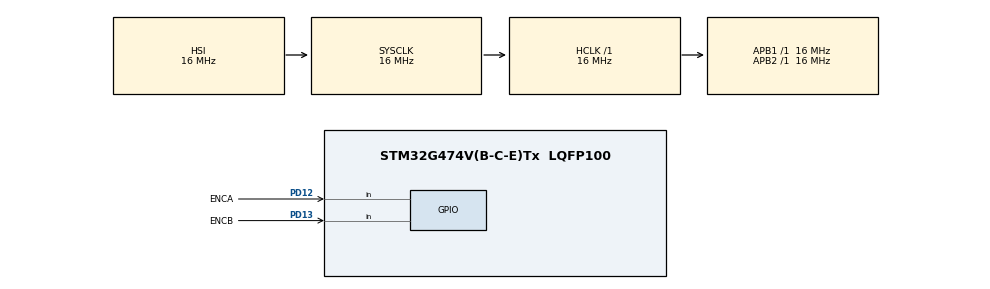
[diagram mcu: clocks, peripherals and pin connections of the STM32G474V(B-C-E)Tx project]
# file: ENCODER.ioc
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Mcu.Family=STM32G4
Mcu.Name=STM32G474V(B-C-E)Tx
Mcu.Package=LQFP100
NVIC.PriorityGroup=NVIC_PRIORITYGROUP_4
PD12.GPIO_Label=ENCA
PD12.GPIO_PuPd=GPIO_PULLUP
PD12.Signal=GPIO_Input
PD13.GPIO_Label=ENCB
PD13.GPIO_PuPd=GPIO_PULLUP
PD13.Signal=GPIO_Input
ProjectManager.HeapSize=0x200
ProjectManager.StackSize=0x400
ProjectManager.TargetToolchain=STM32CubeIDE
RCC.AHBFreq_Value=16000000
RCC.APB1Freq_Value=16000000
RCC.APB1TimFreq_Value=16000000
RCC.APB2Freq_Value=16000000
RCC.APB2TimFreq_Value=16000000
RCC.CortexFreq_Value=16000000
RCC.EXTERNAL_CLOCK_VALUE=12288000
RCC.HCLKFreq_Value=16000000
RCC.HSE_VALUE=8000000
RCC.HSI48_VALUE=48000000
RCC.HSI_VALUE=16000000
RCC.LSE_VALUE=32768
RCC.SYSCLKFreq_VALUE=16000000
RCC.USBFreq_Value=64000000
RCC.VCOOutputFreq_Value=128000000
board=custom

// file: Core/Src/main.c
/* USER CODE BEGIN Header */
/**
  ******************************************************************************
  * @file           : main.c
  * @brief          : Main program body
  ******************************************************************************
  * @attention
  *
  * Copyright (c) 2025 STMicroelectronics.
  * All rights reserved.
  *
  * This software is licensed under terms that can be found in the LICENSE file
  * in the root directory of this software component.
  * If no LICENSE file comes with this software, it is provided AS-IS.
  *
  ******************************************************************************
  */
/* USER CODE END Header */
#include "main.h"

void SystemClock_Config(void);
static void MX_GPIO_Init(void);

/* USER CODE BEGIN 0 */
int encoder = 0;
/* USER CODE END 0 */

int main(void)
{

  /* MCU Configuration--------------------------------------------------------*/

  /* Reset of all peripherals, Initializes the Flash interface and the Systick. */
  HAL_Init();

  /* Configure the system clock */
  SystemClock_Config();

  /* Initialize all configured peripherals */
  MX_GPIO_Init();
  /* USER CODE BEGIN 2 */
int prev = 0b11;
  /* USER CODE END 2 */

  /* Infinite loop */
  while (1)
  {

    /* USER CODE BEGIN 3 */
  	int curr = 0;
  	curr+=HAL_GPIO_ReadPin(ENCA_GPIO_Port, ENCA_Pin) ? 0b01 :0;
  	curr+=HAL_GPIO_ReadPin(ENCB_GPIO_Port, ENCB_Pin) ? 0b10 :0;
  	switch(prev <<2 |curr){
  		case 0b0001:
  		case 0b0111:
  		case 0b1110:
  		case 0b1000:
  			encoder+=1;break; //clockwise
  		case 0b0010:
  		case 0b1011:
  		case 0b1101:
  		case 0b0100:
  			encoder -=1;break;//counterclockwise

  		default: break;

  	}
  	prev = curr;
  	HAL_Delay(0);
  }
  /* USER CODE END 3 */
}

void SystemClock_Config(void)
{
  RCC_OscInitTypeDef RCC_OscInitStruct = {0};
  RCC_ClkInitTypeDef RCC_ClkInitStruct = {0};

  /** Configure the main internal regulator output voltage
  */
  HAL_PWREx_ControlVoltageScaling(PWR_REGULATOR_VOLTAGE_SCALE1);

  /** Initializes the RCC Oscillators according to the specified parameters
  * in the RCC_OscInitTypeDef structure.
  */
  RCC_OscInitStruct.OscillatorType = RCC_OSCILLATORTYPE_HSI;
  RCC_OscInitStruct.HSIState = RCC_HSI_ON;
  RCC_OscInitStruct.HSICalibrationValue = RCC_HSICALIBRATION_DEFAULT;
  RCC_OscInitStruct.PLL.PLLState = RCC_PLL_NONE;
  if (HAL_RCC_OscConfig(&RCC_OscInitStruct) != HAL_OK)
  {
    Error_Handler();
  }

  /** Initializes the CPU, AHB and APB buses clocks
  */
  RCC_ClkInitStruct.ClockType = RCC_CLOCKTYPE_HCLK|RCC_CLOCKTYPE_SYSCLK
                              |RCC_CLOCKTYPE_PCLK1|RCC_CLOCKTYPE_PCLK2;
  RCC_ClkInitStruct.SYSCLKSource = RCC_SYSCLKSOURCE_HSI;
  RCC_ClkInitStruct.AHBCLKDivider = RCC_SYSCLK_DIV1;
  RCC_ClkInitStruct.APB1CLKDivider = RCC_HCLK_DIV1;
  RCC_ClkInitStruct.APB2CLKDivider = RCC_HCLK_DIV1;

  if (HAL_RCC_ClockConfig(&RCC_ClkInitStruct, FLASH_LATENCY_0) != HAL_OK)
  {
    Error_Handler();
  }
}

static void MX_GPIO_Init(void)
{
  GPIO_InitTypeDef GPIO_InitStruct = {0};

  /* GPIO Ports Clock Enable */
  __HAL_RCC_GPIOD_CLK_ENABLE();

  /*Configure GPIO pins : ENCA_Pin ENCB_Pin */
  GPIO_InitStruct.Pin = ENCA_Pin|ENCB_Pin;
  GPIO_InitStruct.Mode = GPIO_MODE_INPUT;
  GPIO_InitStruct.Pull = GPIO_PULLUP;
  HAL_GPIO_Init(GPIOD, &GPIO_InitStruct);

}

void Error_Handler(void)
{
  __disable_irq();
  while (1)
  {
  }
}
